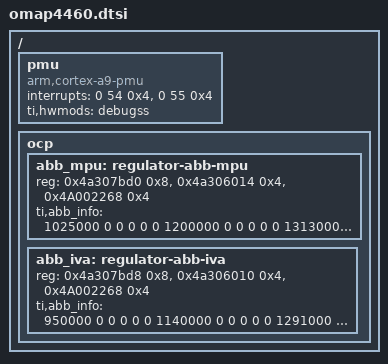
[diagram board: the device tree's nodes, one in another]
/*
 * Device Tree Source for OMAP4460 SoC
 *
 * Copyright (C) 2012 Texas Instruments Incorporated - http://www.ti.com/
 *
 * This file is licensed under the terms of the GNU General Public License
 * version 2.  This program is licensed "as is" without any warranty of any
 * kind, whether express or implied.
 */
/include/ "omap4.dtsi"

/ {
	pmu {
		compatible = "arm,cortex-a9-pmu";
		interrupts = <0 54 0x4>,
			     <0 55 0x4>;
		ti,hwmods = "debugss";
	};

	ocp {
		abb_mpu: regulator-abb-mpu {
			status = "okay";

			reg = <0x4a307bd0 0x8>, <0x4a306014 0x4>,
			      <0x4A002268 0x4>;
			reg-names = "base-address", "int-address",
				    "efuse-address";

			ti,abb_info = <
			/*uV		ABB	efuse	rbb_m	fbb_m	vset_m*/
			1025000		0	0	0	0	0
			1200000		0	0	0	0	0
			1313000		0	0	0x100000 0x40000 0
			1375000		1	0	0	0	0
			1389000		1	0	0	0	0
			>;
		};

		abb_iva: regulator-abb-iva {
			status = "okay";

			reg = <0x4a307bd8 0x8>, <0x4a306010 0x4>,
			      <0x4A002268 0x4>;
			reg-names = "base-address", "int-address",
				    "efuse-address";

			ti,abb_info = <
			/*uV		ABB	efuse	rbb_m	fbb_m	vset_m*/
			950000		0	0	0	0	0
			1140000		0	0	0	0	0
			1291000		0	0	0x200000 0	0
			1375000		1	0	0	0	0
			1376000		1	0	0	0	0
			>;
		};
	};
};
